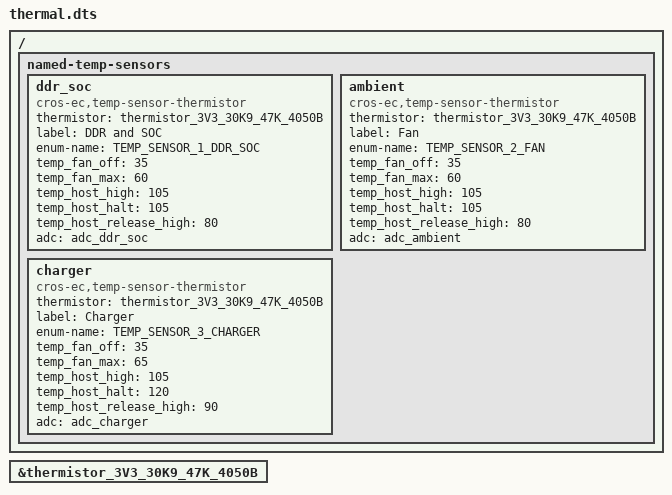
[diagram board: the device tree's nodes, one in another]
/* Copyright 2021 The Chromium OS Authors. All rights reserved.
 * Use of this source code is governed by a BSD-style license that can be
 * found in the LICENSE file.
 */

#include <cros/thermistor/thermistor.dtsi>

/ {
    named-temp-sensors {
		ddr_soc {
			compatible = "cros-ec,temp-sensor-thermistor";
			thermistor = <&thermistor_3V3_30K9_47K_4050B>;
			label = "DDR and SOC";
			enum-name = "TEMP_SENSOR_1_DDR_SOC";
			temp_fan_off = <35>;
			temp_fan_max = <60>;
			temp_host_high = <105>;
			temp_host_halt = <105>;
			temp_host_release_high = <80>;
			adc = <&adc_ddr_soc>;
		};
		ambient {
			compatible = "cros-ec,temp-sensor-thermistor";
			thermistor = <&thermistor_3V3_30K9_47K_4050B>;
			label = "Fan";
			enum-name = "TEMP_SENSOR_2_FAN";
			temp_fan_off = <35>;
			temp_fan_max = <60>;
			temp_host_high = <105>;
			temp_host_halt = <105>;
			temp_host_release_high = <80>;
			adc = <&adc_ambient>;
		};
		charger {
			compatible = "cros-ec,temp-sensor-thermistor";
			thermistor = <&thermistor_3V3_30K9_47K_4050B>;
			label = "Charger";
			enum-name = "TEMP_SENSOR_3_CHARGER";
			temp_fan_off = <35>;
			temp_fan_max = <65>;
			temp_host_high = <105>;
			temp_host_halt = <120>;
			temp_host_release_high = <90>;
			adc = <&adc_charger>;
		};
	};
};

&thermistor_3V3_30K9_47K_4050B {
	status = "okay";
};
